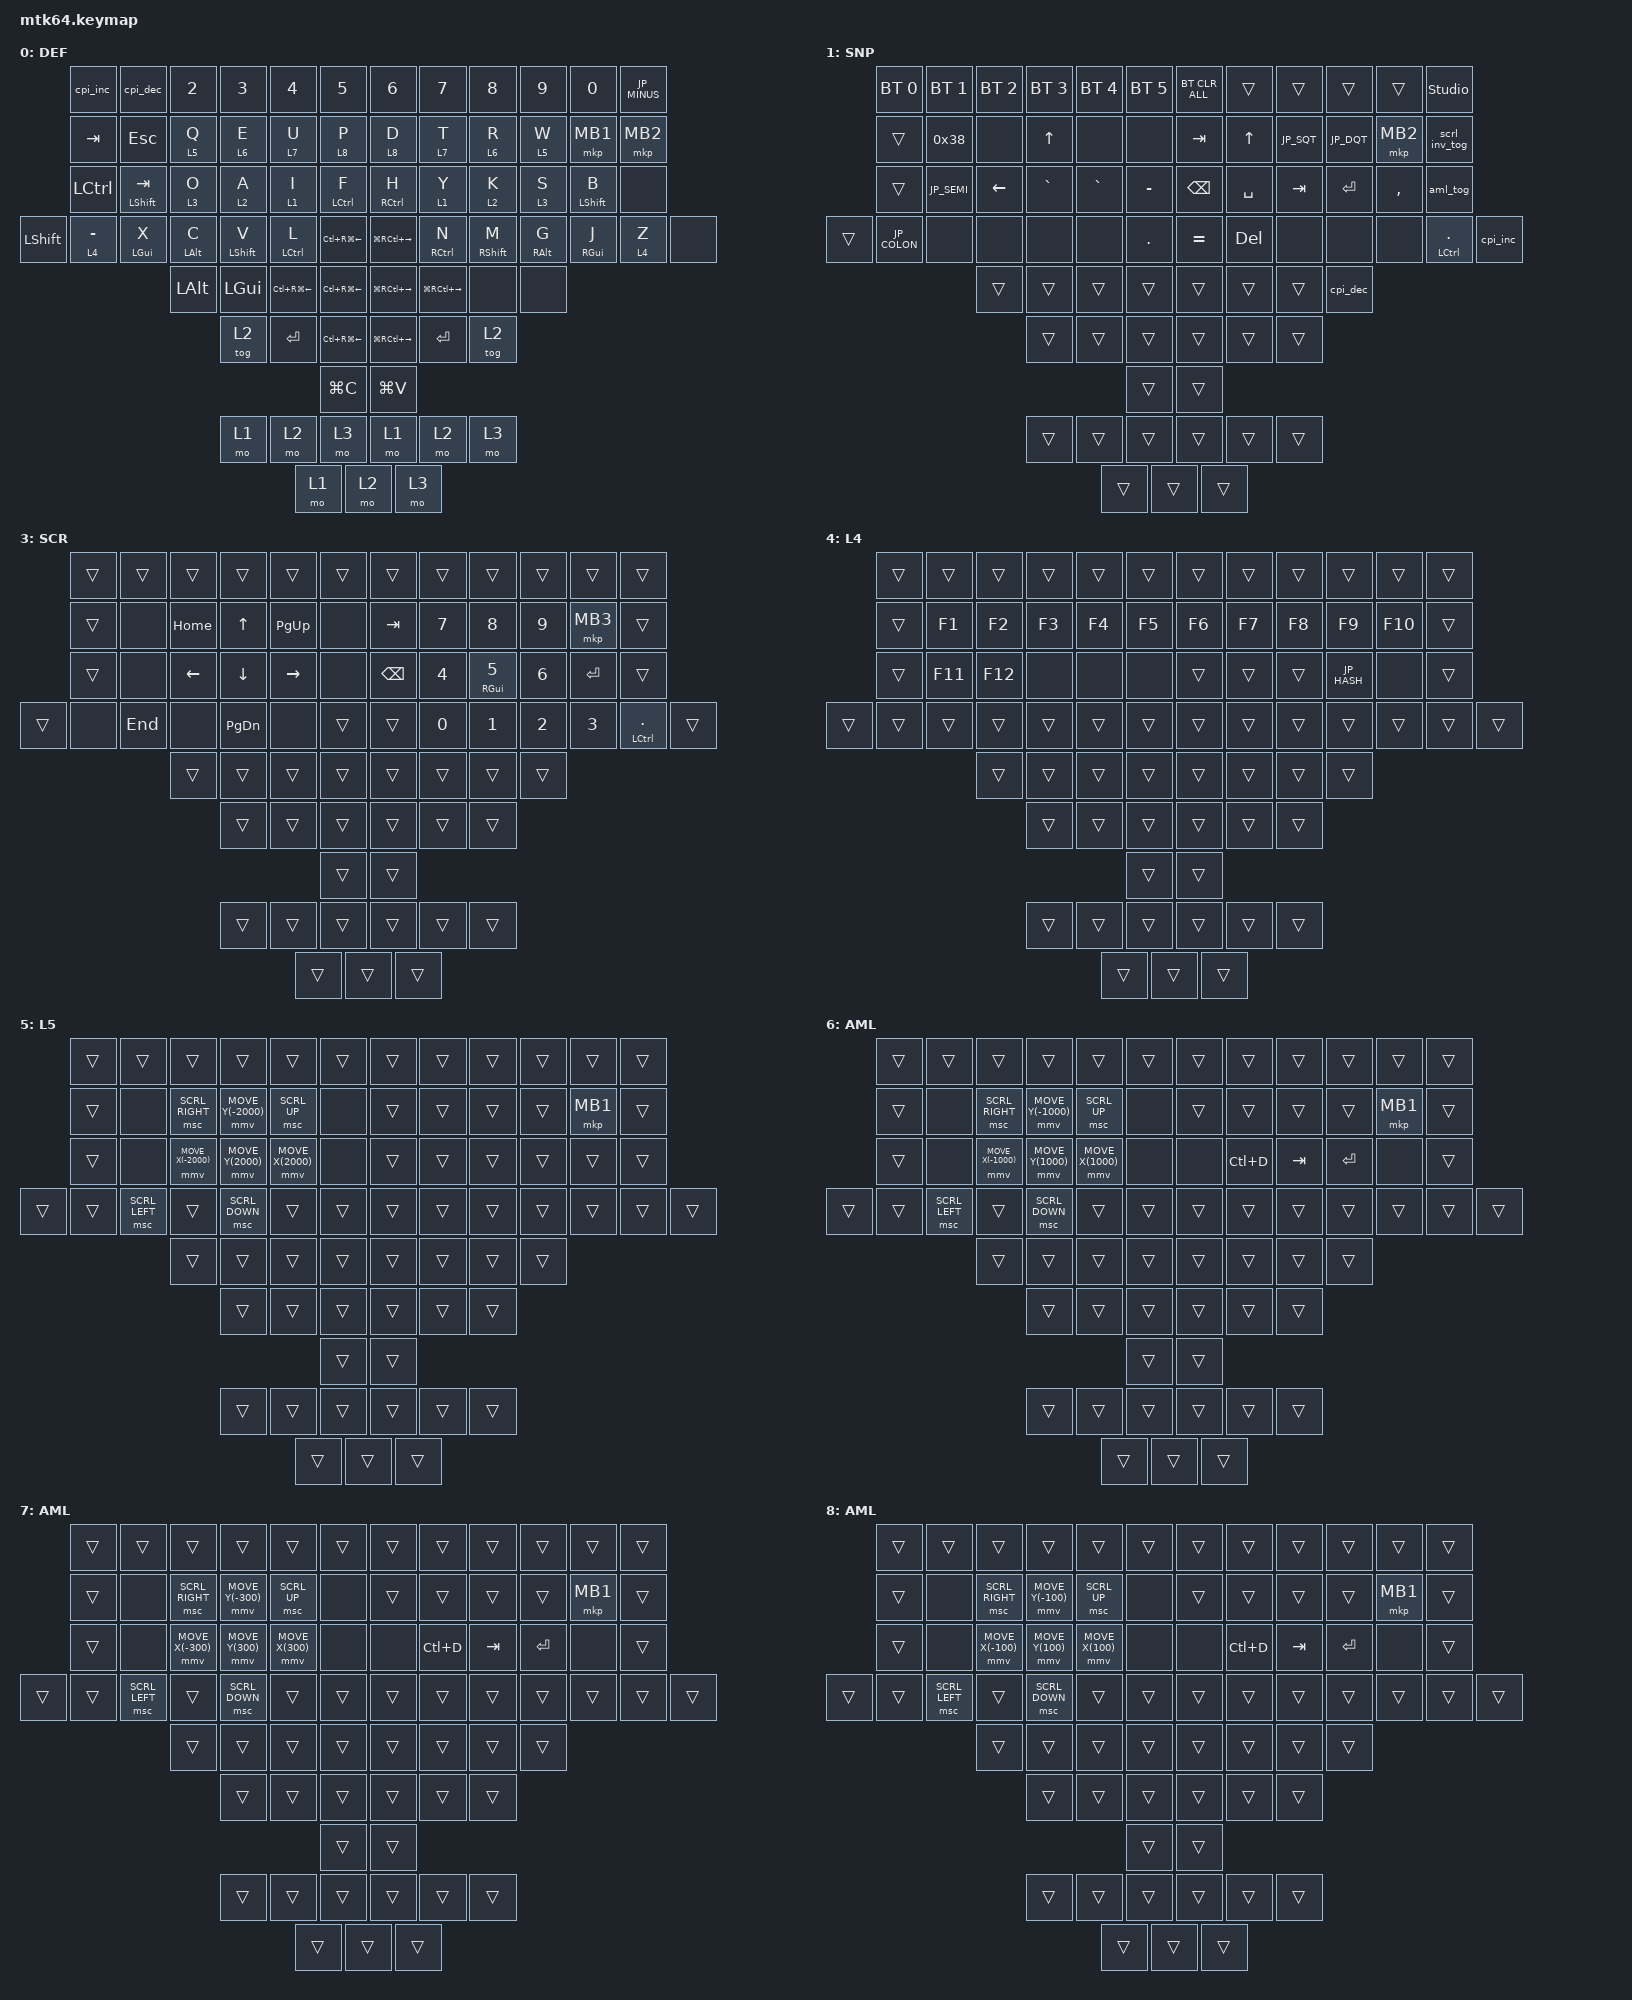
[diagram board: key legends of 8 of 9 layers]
#include <behaviors.dtsi>
#include <dt-bindings/zmk/bt.h>
#include <dt-bindings/zmk/keys.h>
#include <dt-bindings/zmk/pointing.h>
#include <input/processors.dtsi>
#include "keycode_japanese.h"

// スクロール量の設定
#define ZMK_POINTING_DEFAULT_SCRL_VAL 100

&msc {
    acceleration-exponent = <0>;      // 0
    time-to-max-speed-ms = <0>;       // 300
    delay-ms = <0>;                   // 0
};

&mmv {
    time-to-max-speed-ms = <0>;
    acceleration-exponent = <0>;
    trigger-period-ms = <10>;
    delay-ms = <0>;
};

&mt { 
    flavor = "balanced"; 
    tapping-term-ms = <200>;
    quick-tap-ms = <150>; 
};

&lt {
    flavor = "balanced";
    tapping-term-ms = <200>; 
    quick-tap-ms = <150>; 
};

&mkp_input_listener {
    input-processors = <&zip_aml 6 5000>;
};

/ {
    behaviors {
        // 垂直スクロール用のbehaviorの設定
        scroll_up_down: behavior_sensor_rotate_mouse_wheel_up_down {
            compatible = "zmk,behavior-sensor-rotate-var";
            #sensor-binding-cells = <2>;
            bindings = <&msc>, <&msc>;
            tap-ms = <20>; // スクロールのタップ時間
        };
        // 水平スクロール用のbehaviorの設定
        scroll_left_right: behavior_sensor_rotate_mouse_wheel_left_right {
            compatible = "zmk,behavior-sensor-rotate-var";
            #sensor-binding-cells = <2>;
            bindings = <&msc>, <&msc>;
            tap-ms = <20>; // スクロールのタップ時間
        };
    };
};

//mtk64ebt
    // キー番号早見表：
    //0  1  2  3  4  5        6  7  8  9  10 11 
    //12 13 14 15 16 17       18 19 20 21 22 23
    //24 25 26 27 28 29       30 31 32 33 34 35
    //36 37 38 39 40 41 42 43 44 45 46 47 48 49
    
    //50 51        52 53    54 55         56 57      

/{
combos {
        compatible = "zmk,combos";
//        timeout-ms = <100>;
//        require-prior-idle-ms = <150>;



      lang {
            bindings = <&kp GRAVE>;
            key-positions = <14 16>;
            layers = <0>;
            timeout-ms = <200>;
        };

        fopen {
            bindings = <&kp LG(N2)>;
            key-positions = <18 22>;
            layers = <0>;
            timeout-ms = <200>;
        };

       bootloader_R {
            bindings = <&bootloader>;
            key-positions = <6 11 43 49>;
            timeout-ms = <200>;
        };

       bootloader_L {
            bindings = <&bootloader>;
            key-positions = <0 5 36 42>;
            timeout-ms = <200>;
        };

        eq {
            bindings = <&bt BT_CLR_ALL>;
            key-positions = <0 12 24>;
            timeout-ms = <50>;
            layers = <0>;
        };

        bt0 {
            bindings = <&bt BT_SEL 0>;
            key-positions = <6 18 30>;
            timeout-ms = <50>;
            layers = <0>;
        };

        bt1 {
            bindings = <&bt BT_SEL 1>;
            key-positions = <7 19 31>;
            layers = <0>;
        };

        bt2 {
            bindings = <&bt BT_SEL 2>;
            key-positions = <8 20 32>;
            layers = <0>;
        };

        bt3 {
            bindings = <&bt BT_SEL 3>;
            key-positions = <9 21 33>;
            layers = <0>;
        };

        bt4 {
            bindings = <&bt BT_SEL 4>;
            key-positions = <10 22 34>;
            layers = <0>;
        };

        bt5 {
            bindings = <&bt BT_SEL 5>;
            key-positions = <11 23 35>;
            layers = <0>;
        };

        mute {
            bindings = <&kp C_MUTE>;
            key-positions = <28 29>;
            layers = <0>;
        };

        vup {
            bindings = <&kp C_VOL_UP>;
            key-positions = <16 17>;
            layers = <0>;
        };

        vdn {
            bindings = <&kp C_VOL_DN>;
            key-positions = <40 41>;
            layers = <0>;
        };

        printscreen {
            bindings = <&kp PSCRN>;
            key-positions = <38 40>;
            layers = <0>;
        };


        space {
            bindings = <&kp SPACE>;
            key-positions = <25 28>;
            layers = <0>;
            timeout-ms = <250>;
        };





    };
};



/ {

    keymap {
        compatible = "zmk,keymap";

        default_layer {
            display-name = "DEF";
            bindings = <
&cpi_inc   &cpi_dec &kp N2 &kp N3   &kp N4   &kp N5                                                         &kp N6 &kp N7   &kp N8    &kp N9  &kp N0       &kp JP_MINUS

&kp TAB   &kp ESCAPE      &lt 5 Q    &lt 6 E    &lt 7 U       &lt 8 P                                &lt 8 D        &lt 7 T       &lt 6 R     &lt 5 W     &mkp MB1       &mkp MB2
&kp LCTRL &mt LSHIFT TAB  &lt 3 O    &lt 2 A    &lt 1 I       &mt LCTRL F                                 &mt RCTRL H  &lt 1 Y       &lt 2 K     &lt 3 S     &mt LEFT_SHIFT B  &none
&kp LSHFT &lt 4 MINUS     &mt LGUI X &mt LALT C &mt LSHIFT V  &mt LCTRL L &kp LC(RG(LEFT))             &kp LG(RC(RIGHT)) &mt RCTRL N  &mt RSHIFT M  &mt RALT G  &mt RGUI J  &lt 4 Z &none

&kp LALT  &kp LGUI               &kp LC(RG(LEFT))    &kp LC(RG(LEFT))                                           &kp LG(RC(RIGHT))    &kp LG(RC(RIGHT))                        &none &none
                 &tog 2 &kp ENTER               &kp LC(RG(LEFT))                                          &kp LG(RC(RIGHT))                 &kp ENTER &tog 2
                                                 &kp LG(C)                                             &kp LG(V)
          &mo 1  &mo 2  &mo 3                                                                                                    &mo 1     &mo 2   &mo 3
                                                                        &mo 1    &mo 2     &mo 3  
            >;

            sensor-bindings = <
                &inc_dec_kp LEFT_ARROW RIGHT_ARROW
                &inc_dec_kp UP_ARROW   DOWN_ARROW
            >;
        };

        layer_1 {
            display-name = "SNP";
            bindings = <
&bt BT_SEL 0  &bt BT_SEL 1  &bt BT_SEL 2  &bt BT_SEL 3  &bt BT_SEL 4  &bt BT_SEL 5           &bt BT_CLR_ALL  &trans  &trans  &trans  &trans  &studio_unlock

&trans  &kp 0x38      &none      &kp UP     &none      &none                                   &kp TAB        &kp UP     &kp JP_SQT  &kp JP_DQT  &mkp MB2                &scrl_inv_tog  
&trans  &kp JP_SEMI   &kp LEFT   &kp GRAVE  &kp GRAVE  &kp MINUS                                &kp BACKSPACE  &kp SPACE  &kp TAB     &kp ENTER   &kp COMMA              &aml_tog  
&trans  &kp JP_COLON  &none      &none      &none      &none     &kp PERIOD    &kp EQUAL        &kp DELETE     &none      &none       &none       &mt LCTRL PERIOD       &cpi_inc
&trans  &trans                                       &trans        &trans         &trans         &trans                                            &trans                &cpi_dec
                                    &trans           &trans        &trans         &trans                                              &trans          &trans
                                                                                                     &trans         &trans
        &trans                      &trans           &trans                                                                                                             &trans          &trans                &trans
                                                                                                     &trans &trans  &trans 
            >;
        };

        layer_2 {
            display-name = "MSE";
            bindings = <
&trans  &kp F1                      &kp F2           &kp F3           &kp F4           &kp F5                                      &kp F6  &kp F7 &kp F8 &kp F9 &kp F10 &kp F11

&trans  &none        &kp JP_LT      &kp JP_EQUAL   &kp JP_RT    &kp JP_PRCNT                                   &kp JP_DLLR   &kp JP_PLUS  &kp JP_CARET      &kp JP_SLASH  &mkp MB3                &trans  
&trans  &kp JP_LBKT  &kp JP_LPAR    &kp JP_AT      &kp JP_RPAR  &kp JP_RBKT                                 &kp JP_QMARK  &kp JP_HASH  &kp DOUBLE_QUOTES &kp LS(0x87)  &kp LS(0x1e)               &trans  
&trans  &kp JP_TILDE &kp JP_LBRC    &kp JP_AMPS    &kp JP_RBRC  &none            &kp PERIOD    &kp EQUAL      &kp JP_YEN    &none        &kp JP_SQT        &kp JP_PIPE   &none             &trans                &trans  

&trans  &trans                                                                         &trans        &trans         &trans         &trans                                                                     &trans                &trans
                                    &trans           &trans                                          &trans         &trans                                              &trans          &trans
                                                                                                     &trans         &trans
        &trans                      &trans           &trans                                                                                                             &trans          &trans                &trans
                                                                                                     &trans &trans  &trans 
            >;
            sensor-bindings = <
                &inc_dec_kp TAB LS(TAB) 
                &inc_dec_kp PG_UP PG_DN
            >;
        };

        layer_3 {
            display-name = "SCR";
            bindings = <
&trans  &trans  &trans  &trans  &trans  &trans                      &trans  &trans  &trans  &trans  &trans  &trans

&trans   &none        &kp HOME   &kp UP     &kp PAGE_UP      &none                              &kp TAB          &kp N7          &kp N8        &kp N9         &mkp MB3  &trans
&trans  &none        &kp LEFT   &kp DOWN   &kp RIGHT        &none                               &kp BACKSPACE  &kp N4          &mt RGUI N5        &kp N6         &kp ENTER  &trans
&trans  &none        &kp END    &none      &kp PAGE_DOWN    &none       &trans      &trans        &kp N0         &kp N1          &kp N2        &kp N3         &mt LCTRL PERIOD  &trans

&trans  &trans                          &trans  &trans      &trans  &trans                          &trans  &trans
                &trans  &trans                  &trans      &trans                  &trans  &trans
                                                &trans      &trans
        &trans  &trans  &trans                                                      &trans  &trans  &trans
                                               &trans &trans &trans
            >;
            sensor-bindings = <
                &scroll_left_right SCRL_LEFT SCRL_RIGHT
                &scroll_up_down SCRL_UP SCRL_DOWN
            >;
        };

        layer_4 {
            display-name = "L4";
            bindings = <
&trans  &trans  &trans  &trans  &trans  &trans                      &trans  &trans  &trans  &trans  &trans  &trans

&trans  &kp F1   &kp F2    &kp F3  &kp F4  &kp F5                      &kp F6  &kp F7  &kp F8  &kp F9       &kp F10  &trans
&trans  &kp F11  &kp F12   &none   &none   &none                      &trans  &trans  &trans  &kp JP_HASH  &none  &trans
&trans  &trans  &trans  &trans  &trans  &trans          &trans      &trans        &trans  &trans  &trans  &trans  &trans  &trans

&trans  &trans                          &trans  &trans      &trans  &trans                          &trans  &trans
                &trans  &trans                  &trans      &trans                  &trans  &trans
                                                &trans      &trans
        &trans  &trans  &trans                                                      &trans  &trans  &trans
                                               &trans &trans &trans
            >;
        };

        layer_5 {
            display-name = "L5";
            bindings = <
&trans  &trans  &trans  &trans  &trans  &trans                      &trans  &trans  &trans  &trans  &trans  &trans

&trans  &none   &msc SCRL_RIGHT    &mmv MOVE_Y(-2000)  &msc SCRL_UP       &none                                  &trans  &trans  &trans  &trans  &mkp MB1  &trans
&trans  &none   &mmv MOVE_X(-2000) &mmv MOVE_Y(2000)   &mmv MOVE_X(2000)  &none                                  &trans  &trans  &trans  &trans  &trans  &trans
&trans  &trans  &msc SCRL_LEFT     &trans              &msc SCRL_DOWN     &trans       &trans      &trans       &trans  &trans  &trans  &trans  &trans  &trans

&trans  &trans                          &trans  &trans      &trans  &trans                          &trans  &trans
                &trans  &trans                  &trans      &trans                  &trans  &trans
                                                &trans      &trans
        &trans  &trans  &trans                                                      &trans  &trans  &trans
                                               &trans &trans &trans
            >;
        };

        layer_6 {
            display-name = "AML";
            bindings = <
&trans  &trans  &trans  &trans  &trans  &trans                      &trans  &trans  &trans  &trans  &trans  &trans

&trans  &none   &msc SCRL_RIGHT    &mmv MOVE_Y(-1000)  &msc SCRL_UP       &none                                  &trans  &trans  &trans  &trans  &mkp MB1  &trans
&trans  &none   &mmv MOVE_X(-1000) &mmv MOVE_Y(1000)   &mmv MOVE_X(1000)  &none                                  &none  &kp LC(D) &kp TAB  &kp ENTER &none  &trans
&trans  &trans  &msc SCRL_LEFT     &trans              &msc SCRL_DOWN     &trans       &trans      &trans       &trans  &trans  &trans  &trans  &trans  &trans

&trans  &trans                          &trans  &trans      &trans  &trans                          &trans  &trans
                &trans  &trans                  &trans      &trans                  &trans  &trans
                                                &trans      &trans
        &trans  &trans  &trans                                                      &trans  &trans  &trans
                                               &trans &trans &trans
            >;
        };

        layer_7 {
            display-name = "AML";
            bindings = <
&trans  &trans  &trans  &trans  &trans  &trans                      &trans  &trans  &trans  &trans  &trans  &trans

&trans  &none   &msc SCRL_RIGHT    &mmv MOVE_Y(-300)  &msc SCRL_UP       &none                                  &trans  &trans  &trans  &trans  &mkp MB1  &trans
&trans  &none   &mmv MOVE_X(-300) &mmv MOVE_Y(300)   &mmv MOVE_X(300)  &none                                  &none  &kp LC(D) &kp TAB  &kp ENTER &none  &trans
&trans  &trans  &msc SCRL_LEFT     &trans              &msc SCRL_DOWN     &trans       &trans      &trans       &trans  &trans  &trans  &trans  &trans  &trans

&trans  &trans                          &trans  &trans      &trans  &trans                          &trans  &trans
                &trans  &trans                  &trans      &trans                  &trans  &trans
                                                &trans      &trans
        &trans  &trans  &trans                                                      &trans  &trans  &trans
                                               &trans &trans &trans
            >;
        };

        layer_8 {
            display-name = "AML";
            bindings = <
&trans  &trans  &trans  &trans  &trans  &trans                      &trans  &trans  &trans  &trans  &trans  &trans

&trans  &none   &msc SCRL_RIGHT    &mmv MOVE_Y(-100)  &msc SCRL_UP       &none                                  &trans  &trans  &trans  &trans  &mkp MB1  &trans
&trans  &none   &mmv MOVE_X(-100) &mmv MOVE_Y(100)   &mmv MOVE_X(100)  &none                                  &none  &kp LC(D) &kp TAB  &kp ENTER &none  &trans
&trans  &trans  &msc SCRL_LEFT     &trans              &msc SCRL_DOWN     &trans       &trans      &trans       &trans  &trans  &trans  &trans  &trans  &trans

&trans  &trans                          &trans  &trans      &trans  &trans                          &trans  &trans
                &trans  &trans                  &trans      &trans                  &trans  &trans
                                                &trans      &trans
        &trans  &trans  &trans                                                      &trans  &trans  &trans
                                               &trans &trans &trans
            >;
        };


    };
};
